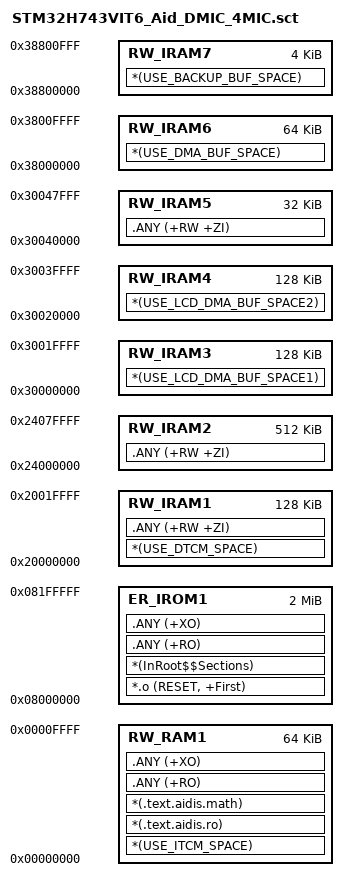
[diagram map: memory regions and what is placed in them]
; *************************************************************
; *** Scatter-Loading Description File generated by uVision ***
; *************************************************************

LR_IROM1 0x08000000 0x00200000  {    ; load region size_region
  ER_IROM1 0x08000000 0x00200000  {  ; load address = execution address
   *.o (RESET, +First)
   *(InRoot$$Sections)
   .ANY (+RO)
   .ANY (+XO)
  }
  RW_RAM1 0x00000000 0x00010000  {  ; 64KB ITCM Code Data 400MHz
	 *(USE_ITCM_SPACE)
	 *(.text.aidis.ro)
   *(.text.aidis.math)
   .ANY (+RO)
   .ANY (+XO)
  }
  RW_IRAM1 0x20000000 0x00020000  { ; 128KB DTCM Data 400MHz
    *(USE_DTCM_SPACE)
   .ANY (+RW +ZI)
  }
  RW_IRAM2 0x24000000 0x00080000  { ; 512KB Main Data 200MHz
   .ANY (+RW +ZI)
  }
	RW_IRAM3 0x30000000 0x00020000  { ; 128KB D2 DMA Data 200MHz
    *(USE_LCD_DMA_BUF_SPACE1)
  }
  RW_IRAM4 0x30020000 0x00020000  { ; 128KB D2 DMA Data 200MHz
    *(USE_LCD_DMA_BUF_SPACE2)
  }
  RW_IRAM5 0x30040000 0x00008000  { ; 32KB D2 DMA Data 200MHz
    .ANY (+RW +ZI)
  }	
  RW_IRAM6 0x38000000 0x00010000  { ; 64KB D3 DMA Data 200MHz
   *(USE_DMA_BUF_SPACE)
  }
	RW_IRAM7 0x38800000 0x00001000  {	; 4KB Low Power Save Data 200MHz
   *(USE_BACKUP_BUF_SPACE)
  }
}
